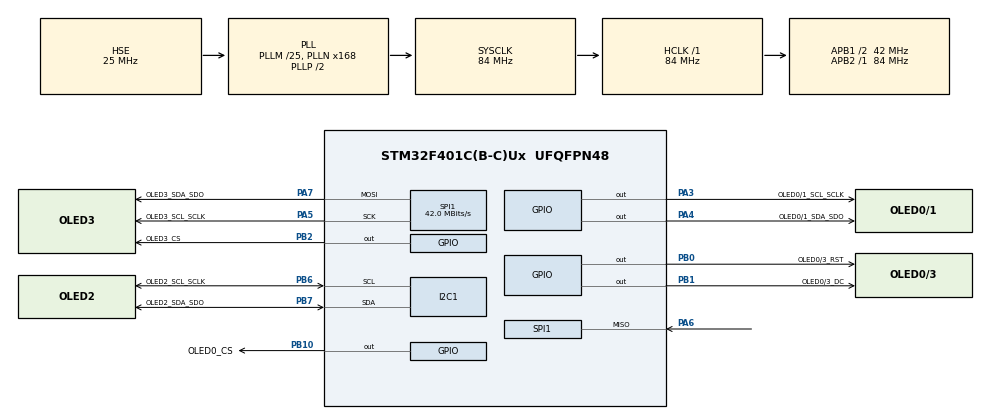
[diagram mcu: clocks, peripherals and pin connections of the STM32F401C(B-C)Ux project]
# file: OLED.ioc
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I2C1.I2C_Mode=I2C_Fast
Mcu.Family=STM32F4
Mcu.Name=STM32F401C(B-C)Ux
Mcu.Package=UFQFPN48
NVIC.PriorityGroup=NVIC_PRIORITYGROUP_4
PA13.Mode=Serial_Wire
PA13.Signal=SYS_JTMS-SWDIO
PA14.Mode=Serial_Wire
PA14.Signal=SYS_JTCK-SWCLK
PA3.GPIO_Label=OLED0/1_SCL_SCLK
PA3.Signal=GPIO_Output
PA4.GPIO_Label=OLED0/1_SDA_SDO
PA4.Signal=GPIO_Output
PA5.GPIO_Label=OLED3_SCL_SCLK
PA5.Mode=Full_Duplex_Master
PA5.Signal=SPI1_SCK
PA5.Stacked=true
PA6.Mode=Full_Duplex_Master
PA6.Signal=SPI1_MISO
PA7.GPIO_Label=OLED3_SDA_SDO
PA7.Mode=Full_Duplex_Master
PA7.Signal=SPI1_MOSI
PA7.Stacked=true
PB0.GPIO_Label=OLED0/3_RST
PB0.Signal=GPIO_Output
PB1.GPIO_Label=OLED0/3_DC
PB1.GPIO_Speed=GPIO_SPEED_FREQ_VERY_HIGH
PB1.PinState=GPIO_PIN_SET
PB1.Signal=GPIO_Output
PB10.GPIO_Label=OLED0_CS
PB10.Signal=GPIO_Output
PB2.GPIO_Label=OLED3_CS
PB2.Signal=GPIO_Output
PB6.GPIO_Label=OLED2_SCL_SCLK
PB6.GPIO_Mode=GPIO_MODE_AF_OD
PB6.GPIO_Pu=GPIO_NOPULL
PB6.GPIO_Speed=GPIO_SPEED_FREQ_VERY_HIGH
PB6.Mode=I2C
PB6.Signal=I2C1_SCL
PB7.GPIO_Label=OLED2_SDA_SDO
PB7.GPIO_Mode=GPIO_MODE_AF_OD
PB7.GPIO_Pu=GPIO_NOPULL
PB7.GPIO_Speed=GPIO_SPEED_FREQ_VERY_HIGH
PB7.Mode=I2C
PB7.Signal=I2C1_SDA
PH0\ -\ OSC_IN.Mode=HSE-External-Oscillator
PH0\ -\ OSC_IN.Signal=RCC_OSC_IN
PH1\ -\ OSC_OUT.Mode=HSE-External-Oscillator
PH1\ -\ OSC_OUT.Signal=RCC_OSC_OUT
ProjectManager.HeapSize=0x200
ProjectManager.StackSize=0x400
ProjectManager.TargetToolchain=MDK-ARM V5.27
RCC.48MHZClocksFreq_Value=42000000
RCC.AHBFreq_Value=84000000
RCC.APB1CLKDivider=RCC_HCLK_DIV2
RCC.APB1Freq_Value=42000000
RCC.APB1TimFreq_Value=84000000
RCC.APB2Freq_Value=84000000
RCC.APB2TimFreq_Value=84000000
RCC.CortexFreq_Value=84000000
RCC.HCLKFreq_Value=84000000
RCC.HSE_VALUE=25000000
RCC.HSI_VALUE=16000000
RCC.LSE_VALUE=32768
RCC.PLLM=25
RCC.PLLN=168
RCC.PLLSourceVirtual=RCC_PLLSOURCE_HSE
RCC.SYSCLKFreq_VALUE=84000000
RCC.SYSCLKSource=RCC_SYSCLKSOURCE_PLLCLK
RCC.VCOOutputFreq_Value=168000000
SPI1.CalculateBaudRate=42.0 MBits/s
SPI1.Direction=SPI_DIRECTION_2LINES
SPI1.Mode=SPI_MODE_MASTER
SPI1.VirtualType=VM_MASTER
board=custom

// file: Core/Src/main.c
/* USER CODE BEGIN Header */
/**
  ******************************************************************************
  * @file           : main.c
  * @brief          : Main program body
  ******************************************************************************
  * @attention
  *
  * <h2><center>&copy; Copyright (c) 2021 STMicroelectronics.
  * All rights reserved.</center></h2>
  *
  * This software component is licensed by ST under BSD 3-Clause license,
  * the "License"; You may not use this file except in compliance with the
  * License. You may obtain a copy of the License at:
  *                        opensource.org/licenses/BSD-3-Clause
  *
  ******************************************************************************
  */
/* USER CODE END Header */
#include "main.h"

/* USER CODE BEGIN Includes */
#include "oledlib.h"
/* USER CODE END Includes */

I2C_HandleTypeDef hi2c1;

SPI_HandleTypeDef hspi1;

void SystemClock_Config(void);
static void MX_GPIO_Init(void);
static void MX_I2C1_Init(void);
static void MX_SPI1_Init(void);

int main(void)
{

  /* MCU Configuration--------------------------------------------------------*/

  /* Reset of all peripherals, Initializes the Flash interface and the Systick. */
  HAL_Init();

  /* Configure the system clock */
  SystemClock_Config();

  /* Initialize all configured peripherals */
  MX_GPIO_Init();
  MX_I2C1_Init();
  MX_SPI1_Init();
  /* USER CODE BEGIN 2 */
  OLED_Confi();
  /* USER CODE END 2 */

  /* Infinite loop */
  while(1)
  {

    /* USER CODE BEGIN 3 */
        OLED_clearBuffer();
        OLED_Bitmap(0,0,128,40,Like);
        OLED_updateScreen(0);

        OLED_clearBuffer();
        OLED_Bitmap(0,0,128,64,Panda);
        OLED_updateScreen(1);

        OLED_clearBuffer();
        OLED_Bitmap(0,0,64,64,BmpTest3);
        OLED_updateScreen(2);

        OLED_clearBuffer();
        OLED_Chinese(0,16*1,"测试");
        OLED_updateScreen(3);
  }
  /* USER CODE END 3 */
}

void SystemClock_Config(void)
{
  RCC_OscInitTypeDef RCC_OscInitStruct = {0};
  RCC_ClkInitTypeDef RCC_ClkInitStruct = {0};

  /** Configure the main internal regulator output voltage
  */
  __HAL_RCC_PWR_CLK_ENABLE();
  __HAL_PWR_VOLTAGESCALING_CONFIG(PWR_REGULATOR_VOLTAGE_SCALE2);
  /** Initializes the RCC Oscillators according to the specified parameters
  * in the RCC_OscInitTypeDef structure.
  */
  RCC_OscInitStruct.OscillatorType = RCC_OSCILLATORTYPE_HSE;
  RCC_OscInitStruct.HSEState = RCC_HSE_ON;
  RCC_OscInitStruct.PLL.PLLState = RCC_PLL_ON;
  RCC_OscInitStruct.PLL.PLLSource = RCC_PLLSOURCE_HSE;
  RCC_OscInitStruct.PLL.PLLM = 25;
  RCC_OscInitStruct.PLL.PLLN = 168;
  RCC_OscInitStruct.PLL.PLLP = RCC_PLLP_DIV2;
  RCC_OscInitStruct.PLL.PLLQ = 4;
  if (HAL_RCC_OscConfig(&RCC_OscInitStruct) != HAL_OK)
  {
    Error_Handler();
  }
  /** Initializes the CPU, AHB and APB buses clocks
  */
  RCC_ClkInitStruct.ClockType = RCC_CLOCKTYPE_HCLK|RCC_CLOCKTYPE_SYSCLK
                              |RCC_CLOCKTYPE_PCLK1|RCC_CLOCKTYPE_PCLK2;
  RCC_ClkInitStruct.SYSCLKSource = RCC_SYSCLKSOURCE_PLLCLK;
  RCC_ClkInitStruct.AHBCLKDivider = RCC_SYSCLK_DIV1;
  RCC_ClkInitStruct.APB1CLKDivider = RCC_HCLK_DIV2;
  RCC_ClkInitStruct.APB2CLKDivider = RCC_HCLK_DIV1;

  if (HAL_RCC_ClockConfig(&RCC_ClkInitStruct, FLASH_LATENCY_2) != HAL_OK)
  {
    Error_Handler();
  }
}

static void MX_I2C1_Init(void)
{

  hi2c1.Instance = I2C1;
  hi2c1.Init.ClockSpeed = 400000;
  hi2c1.Init.DutyCycle = I2C_DUTYCYCLE_2;
  hi2c1.Init.OwnAddress1 = 0;
  hi2c1.Init.AddressingMode = I2C_ADDRESSINGMODE_7BIT;
  hi2c1.Init.DualAddressMode = I2C_DUALADDRESS_DISABLE;
  hi2c1.Init.OwnAddress2 = 0;
  hi2c1.Init.GeneralCallMode = I2C_GENERALCALL_DISABLE;
  hi2c1.Init.NoStretchMode = I2C_NOSTRETCH_DISABLE;
  if (HAL_I2C_Init(&hi2c1) != HAL_OK)
  {
    Error_Handler();
  }

}

static void MX_SPI1_Init(void)
{

  /* SPI1 parameter configuration*/
  hspi1.Instance = SPI1;
  hspi1.Init.Mode = SPI_MODE_MASTER;
  hspi1.Init.Direction = SPI_DIRECTION_2LINES;
  hspi1.Init.DataSize = SPI_DATASIZE_8BIT;
  hspi1.Init.CLKPolarity = SPI_POLARITY_LOW;
  hspi1.Init.CLKPhase = SPI_PHASE_1EDGE;
  hspi1.Init.NSS = SPI_NSS_SOFT;
  hspi1.Init.BaudRatePrescaler = SPI_BAUDRATEPRESCALER_2;
  hspi1.Init.FirstBit = SPI_FIRSTBIT_MSB;
  hspi1.Init.TIMode = SPI_TIMODE_DISABLE;
  hspi1.Init.CRCCalculation = SPI_CRCCALCULATION_DISABLE;
  hspi1.Init.CRCPolynomial = 10;
  if (HAL_SPI_Init(&hspi1) != HAL_OK)
  {
    Error_Handler();
  }

}

static void MX_GPIO_Init(void)
{
  GPIO_InitTypeDef GPIO_InitStruct = {0};

  /* GPIO Ports Clock Enable */
  __HAL_RCC_GPIOH_CLK_ENABLE();
  __HAL_RCC_GPIOA_CLK_ENABLE();
  __HAL_RCC_GPIOB_CLK_ENABLE();

  /*Configure GPIO pin Output Level */
  HAL_GPIO_WritePin(GPIOA, OLED0_1_SCL_SCLK_Pin|OLED0_1_SDA_SDO_Pin, GPIO_PIN_RESET);

  /*Configure GPIO pin Output Level */
  HAL_GPIO_WritePin(GPIOB, OLED0_3_RST_Pin|OLED3_CS_Pin|OLED0_CS_Pin, GPIO_PIN_RESET);

  /*Configure GPIO pin Output Level */
  HAL_GPIO_WritePin(OLED0_3_DC_GPIO_Port, OLED0_3_DC_Pin, GPIO_PIN_SET);

  /*Configure GPIO pins : OLED0_1_SCL_SCLK_Pin OLED0_1_SDA_SDO_Pin */
  GPIO_InitStruct.Pin = OLED0_1_SCL_SCLK_Pin|OLED0_1_SDA_SDO_Pin;
  GPIO_InitStruct.Mode = GPIO_MODE_OUTPUT_PP;
  GPIO_InitStruct.Pull = GPIO_NOPULL;
  GPIO_InitStruct.Speed = GPIO_SPEED_FREQ_LOW;
  HAL_GPIO_Init(GPIOA, &GPIO_InitStruct);

  /*Configure GPIO pins : OLED0_3_RST_Pin OLED3_CS_Pin OLED0_CS_Pin */
  GPIO_InitStruct.Pin = OLED0_3_RST_Pin|OLED3_CS_Pin|OLED0_CS_Pin;
  GPIO_InitStruct.Mode = GPIO_MODE_OUTPUT_PP;
  GPIO_InitStruct.Pull = GPIO_NOPULL;
  GPIO_InitStruct.Speed = GPIO_SPEED_FREQ_LOW;
  HAL_GPIO_Init(GPIOB, &GPIO_InitStruct);

  /*Configure GPIO pin : OLED0_3_DC_Pin */
  GPIO_InitStruct.Pin = OLED0_3_DC_Pin;
  GPIO_InitStruct.Mode = GPIO_MODE_OUTPUT_PP;
  GPIO_InitStruct.Pull = GPIO_NOPULL;
  GPIO_InitStruct.Speed = GPIO_SPEED_FREQ_VERY_HIGH;
  HAL_GPIO_Init(OLED0_3_DC_GPIO_Port, &GPIO_InitStruct);

}

void Error_Handler(void)
{
  __disable_irq();
  while (1)
  {
  }
}

/************************ (C) COPYRIGHT STMicroelectronics *****END OF FILE****/
